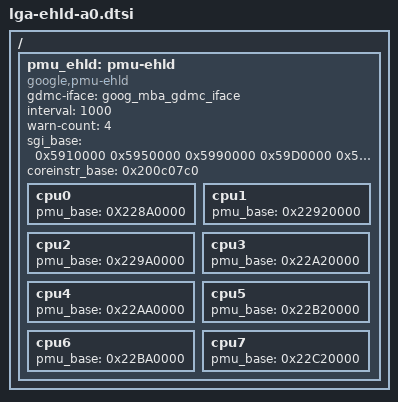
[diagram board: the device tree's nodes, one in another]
// SPDX-License-Identifier: GPL-2.0 OR BSD-3-Clause
/*
 * Copyright 2024 Google LLC.
 */

/ {
	pmu_ehld: pmu-ehld {
		compatible = "google,pmu-ehld";
		gdmc-iface = <&goog_mba_gdmc_iface>;
		interval = <1000>;
		warn-count = <4>;
		sgi_base = /bits/ 64 <0x5910000 0x5950000 0x5990000 0x59D0000
				0x5A10000 0x5A50000 0x5A90000 0x5AD0000>;
		coreinstr_base = <0x200c07c0>;

		cpu0 {
			pmu_base = /bits/ 64 <0X228A0000>;
		};
		cpu1 {
			pmu_base = /bits/ 64 <0x22920000>;
		};
		cpu2 {
			pmu_base = /bits/ 64 <0x229A0000>;
		};
		cpu3 {
			pmu_base = /bits/ 64 <0x22A20000>;
		};
		cpu4 {
			pmu_base = /bits/ 64 <0x22AA0000>;
		};
		cpu5 {
			pmu_base = /bits/ 64 <0x22B20000>;
		};
		cpu6 {
			pmu_base = /bits/ 64 <0x22BA0000>;
		};
		cpu7 {
			pmu_base = /bits/ 64 <0x22C20000>;
		};
	};
};
